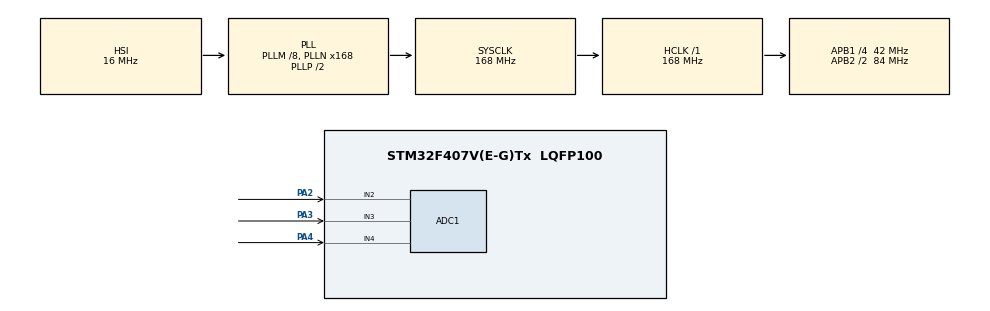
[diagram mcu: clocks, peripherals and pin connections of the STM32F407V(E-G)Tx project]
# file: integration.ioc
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ADC1.Channel-0\#ChannelRegularConversion=ADC_CHANNEL_2
ADC1.Channel-1\#ChannelRegularConversion=ADC_CHANNEL_3
ADC1.Channel-2\#ChannelRegularConversion=ADC_CHANNEL_4
ADC1.ContinuousConvMode=ENABLE
ADC1.DMAContinuousRequests=ENABLE
ADC1.NbrOfConversion=3
ADC1.NbrOfConversionFlag=1
ADC1.Rank-0\#ChannelRegularConversion=1
ADC1.Rank-1\#ChannelRegularConversion=2
ADC1.Rank-2\#ChannelRegularConversion=3
ADC1.SamplingTime-0\#ChannelRegularConversion=ADC_SAMPLETIME_56CYCLES
ADC1.SamplingTime-1\#ChannelRegularConversion=ADC_SAMPLETIME_56CYCLES
ADC1.SamplingTime-2\#ChannelRegularConversion=ADC_SAMPLETIME_56CYCLES
ADC1.ScanConvMode=ENABLE
ADC1.master=1
Dma.ADC1.0.Direction=DMA_PERIPH_TO_MEMORY
Dma.ADC1.0.FIFOMode=DMA_FIFOMODE_DISABLE
Dma.ADC1.0.Instance=DMA2_Stream0
Dma.ADC1.0.MemDataAlignment=DMA_MDATAALIGN_HALFWORD
Dma.ADC1.0.MemInc=DMA_MINC_ENABLE
Dma.ADC1.0.Mode=DMA_CIRCULAR
Dma.ADC1.0.PeriphDataAlignment=DMA_PDATAALIGN_HALFWORD
Dma.ADC1.0.PeriphInc=DMA_PINC_DISABLE
Dma.ADC1.0.Priority=DMA_PRIORITY_LOW
Dma.Request0=ADC1
Mcu.Family=STM32F4
Mcu.Name=STM32F407V(E-G)Tx
Mcu.Package=LQFP100
NVIC.DMA2_Stream0_IRQn=true\:0\:0\:false\:false\:true\:false\:true
NVIC.PriorityGroup=NVIC_PRIORITYGROUP_4
NVIC.TIM2_IRQn=true\:0\:0\:false\:false\:true\:true\:true
PA2.Signal=ADCx_IN2
PA3.Signal=ADCx_IN3
PA4.Signal=ADCx_IN4
ProjectManager.HeapSize=0x200
ProjectManager.StackSize=0x400
ProjectManager.TargetToolchain=MDK-ARM V5.27
RCC.48MHZClocksFreq_Value=84000000
RCC.AHBFreq_Value=168000000
RCC.APB1CLKDivider=RCC_HCLK_DIV4
RCC.APB1Freq_Value=42000000
RCC.APB1TimFreq_Value=84000000
RCC.APB2CLKDivider=RCC_HCLK_DIV2
RCC.APB2Freq_Value=84000000
RCC.APB2TimFreq_Value=168000000
RCC.CortexFreq_Value=168000000
RCC.HCLKFreq_Value=168000000
RCC.HSE_VALUE=25000000
RCC.HSI_VALUE=16000000
RCC.LSE_VALUE=32768
RCC.PLLM=8
RCC.PLLN=168
RCC.SYSCLKFreq_VALUE=168000000
RCC.SYSCLKSource=RCC_SYSCLKSOURCE_PLLCLK
RCC.VCOOutputFreq_Value=336000000
SH.ADCx_IN2.0=ADC1_IN2,IN2
SH.ADCx_IN3.0=ADC1_IN3,IN3
SH.ADCx_IN4.0=ADC1_IN4,IN4
TIM2.Period=100
TIM2.Prescaler=42000
TIM2.TIM_MasterOutputTrigger=TIM_TRGO_UPDATE
VP_TIM2_VS_ClockSourceINT.Mode=Internal
board=custom

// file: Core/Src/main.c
/* USER CODE BEGIN Header */
/**
  ******************************************************************************
  * @file           : main.c
  * @brief          : Main program body
  ******************************************************************************
  * @attention
  *
  * <h2><center>&copy; Copyright (c) 2021 STMicroelectronics.
  * All rights reserved.</center></h2>
  *
  * This software component is licensed by ST under BSD 3-Clause license,
  * the "License"; You may not use this file except in compliance with the
  * License. You may obtain a copy of the License at:
  *                        opensource.org/licenses/BSD-3-Clause
  *
  ******************************************************************************
  */
/* USER CODE END Header */
#include "main.h"
#include "adc.h"
#include "dma.h"
#include "tim.h"
#include "gpio.h"

/* USER CODE BEGIN PV */
uint16_t adcArr[3];
uint32_t counter_cur=0;
uint32_t counter_pre=0;
int32_t period = 0;
int16_t velocity=0;
int16_t velocity_pre = 0;
int16_t velocity_dalta=0;
double integretion=0;
double differential=0;

/* USER CODE END PV */

void SystemClock_Config(void);

int main(void)
{

  /* MCU Configuration--------------------------------------------------------*/

  /* Reset of all peripherals, Initializes the Flash interface and the Systick. */
  HAL_Init();

  /* Configure the system clock */
  SystemClock_Config();

  /* Initialize all configured peripherals */
  MX_GPIO_Init();
  MX_DMA_Init();
  MX_ADC1_Init();
  MX_TIM2_Init();
  /* USER CODE BEGIN 2 */
	HAL_ADC_Start_DMA(&hadc1,(uint32_t *)adcArr,3);
	HAL_TIM_Base_Start_IT(&htim2);
  /* USER CODE END 2 */

  /* Infinite loop */
  while (1)
  {

  }
}

void SystemClock_Config(void)
{
  RCC_OscInitTypeDef RCC_OscInitStruct = {0};
  RCC_ClkInitTypeDef RCC_ClkInitStruct = {0};

  /** Configure the main internal regulator output voltage
  */
  __HAL_RCC_PWR_CLK_ENABLE();
  __HAL_PWR_VOLTAGESCALING_CONFIG(PWR_REGULATOR_VOLTAGE_SCALE1);
  /** Initializes the RCC Oscillators according to the specified parameters
  * in the RCC_OscInitTypeDef structure.
  */
  RCC_OscInitStruct.OscillatorType = RCC_OSCILLATORTYPE_HSI;
  RCC_OscInitStruct.HSIState = RCC_HSI_ON;
  RCC_OscInitStruct.HSICalibrationValue = RCC_HSICALIBRATION_DEFAULT;
  RCC_OscInitStruct.PLL.PLLState = RCC_PLL_ON;
  RCC_OscInitStruct.PLL.PLLSource = RCC_PLLSOURCE_HSI;
  RCC_OscInitStruct.PLL.PLLM = 8;
  RCC_OscInitStruct.PLL.PLLN = 168;
  RCC_OscInitStruct.PLL.PLLP = RCC_PLLP_DIV2;
  RCC_OscInitStruct.PLL.PLLQ = 4;
  if (HAL_RCC_OscConfig(&RCC_OscInitStruct) != HAL_OK)
  {
    Error_Handler();
  }
  /** Initializes the CPU, AHB and APB buses clocks
  */
  RCC_ClkInitStruct.ClockType = RCC_CLOCKTYPE_HCLK|RCC_CLOCKTYPE_SYSCLK
                              |RCC_CLOCKTYPE_PCLK1|RCC_CLOCKTYPE_PCLK2;
  RCC_ClkInitStruct.SYSCLKSource = RCC_SYSCLKSOURCE_PLLCLK;
  RCC_ClkInitStruct.AHBCLKDivider = RCC_SYSCLK_DIV1;
  RCC_ClkInitStruct.APB1CLKDivider = RCC_HCLK_DIV4;
  RCC_ClkInitStruct.APB2CLKDivider = RCC_HCLK_DIV2;

  if (HAL_RCC_ClockConfig(&RCC_ClkInitStruct, FLASH_LATENCY_5) != HAL_OK)
  {
    Error_Handler();
  }
}

/* USER CODE BEGIN 4 */
void HAL_TIM_PeriodElapsedCallback(TIM_HandleTypeDef *htim)
{
  /* Prevent unused argument(s) compilation warning */
  UNUSED(htim);

  /* NOTE : This function should not be modified, when the callback is needed,
            the HAL_TIM_PeriodElapsedCallback could be implemented in the user file
   */
	velocity=adcArr[0]-2047;

	counter_cur = HAL_GetTick();
	period = counter_cur-counter_pre;
	velocity_dalta=velocity-velocity_pre;
	integretion+=(double)(period*velocity)*0.00001;
	differential=((double)velocity_dalta/(double)period);
	counter_pre=counter_cur;
	velocity_pre=velocity;
}

/* USER CODE END 4 */

void Error_Handler(void)
{
}

/************************ (C) COPYRIGHT STMicroelectronics *****END OF FILE****/
